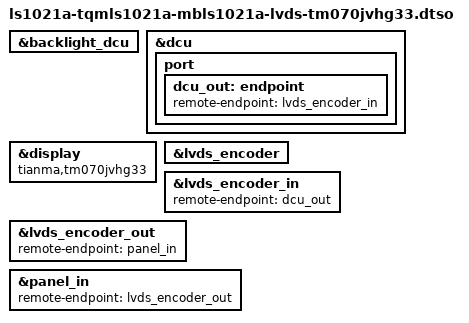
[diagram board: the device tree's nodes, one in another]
// SPDX-License-Identifier: (GPL-2.0-or-later OR MIT)
/*
 * Copyright 2013-2014 Freescale Semiconductor, Inc.
 * Copyright 2018-2025 TQ-Systems GmbH <linux@ew.tq-group.com>,
 * D-82229 Seefeld, Germany.
 * Author: Alexander Stein
 */

#include <dt-bindings/gpio/gpio.h>

/dts-v1/;
/plugin/;

&backlight_dcu {
	status = "okay";
};

&dcu {
	status = "okay";

	port {
		dcu_out: endpoint {
			remote-endpoint = <&lvds_encoder_in>;
		};
	};
};

&display {
	compatible = "tianma,tm070jvhg33";
	status = "okay";
};

&lvds_encoder {
	status = "okay";
};

&lvds_encoder_in {
	remote-endpoint = <&dcu_out>;
};

&lvds_encoder_out {
	remote-endpoint = <&panel_in>;
};

&panel_in {
	remote-endpoint = <&lvds_encoder_out>;
};
